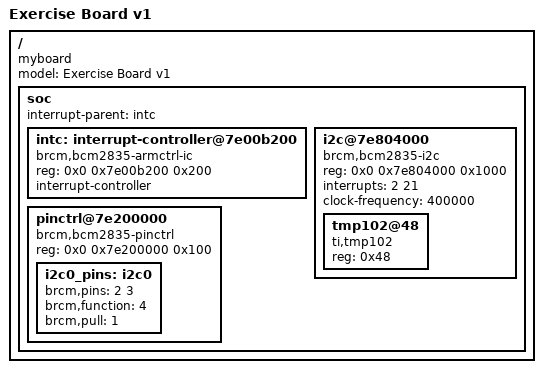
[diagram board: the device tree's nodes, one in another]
/dts-v1/;
/ {
	compatible = "myboard";
	model = "Exercise Board v1";

	#address-cells = <2>;
	#size-cells = <1>;

	soc {
		#address-cells = <2>;
		#size-cells = <1>;
		ranges;

		interrupt-parent = <&intc>;

		intc: interrupt-controller@7e00b200 {
			compatible = "brcm,bcm2835-armctrl-ic";
			reg = <0x0 0x7e00b200 0x200>;
			interrupt-controller;
			#interrupt-cells = <2>;
		};

		i2c@7e804000 {
			compatible = "brcm,bcm2835-i2c";
			reg = <0x0 0x7e804000 0x1000>;
			interrupts = <2 21>;
			clock-frequency = <400000>;	/* 400KHz */
			status = "okay";
			#address-cells = <1>;
			#size-cells = <0>;

			tmp102@48 {
				compatible = "ti,tmp102";
				reg = <0x48>;
			};
		};

		pinctrl@7e200000 {
			compatible = "brcm,bcm2835-pinctrl";
			reg = <0x0 0x7e200000 0x100>;
			i2c0_pins: i2c0 {
				brcm,pins = <2 3>; /* SDA: GPIO2, SCL: GPIO3 */
				brcm,function = <4>; /* ALT0 */
				brcm,pull = <1>; /* Pull-up */
			};
		};
	};
};
